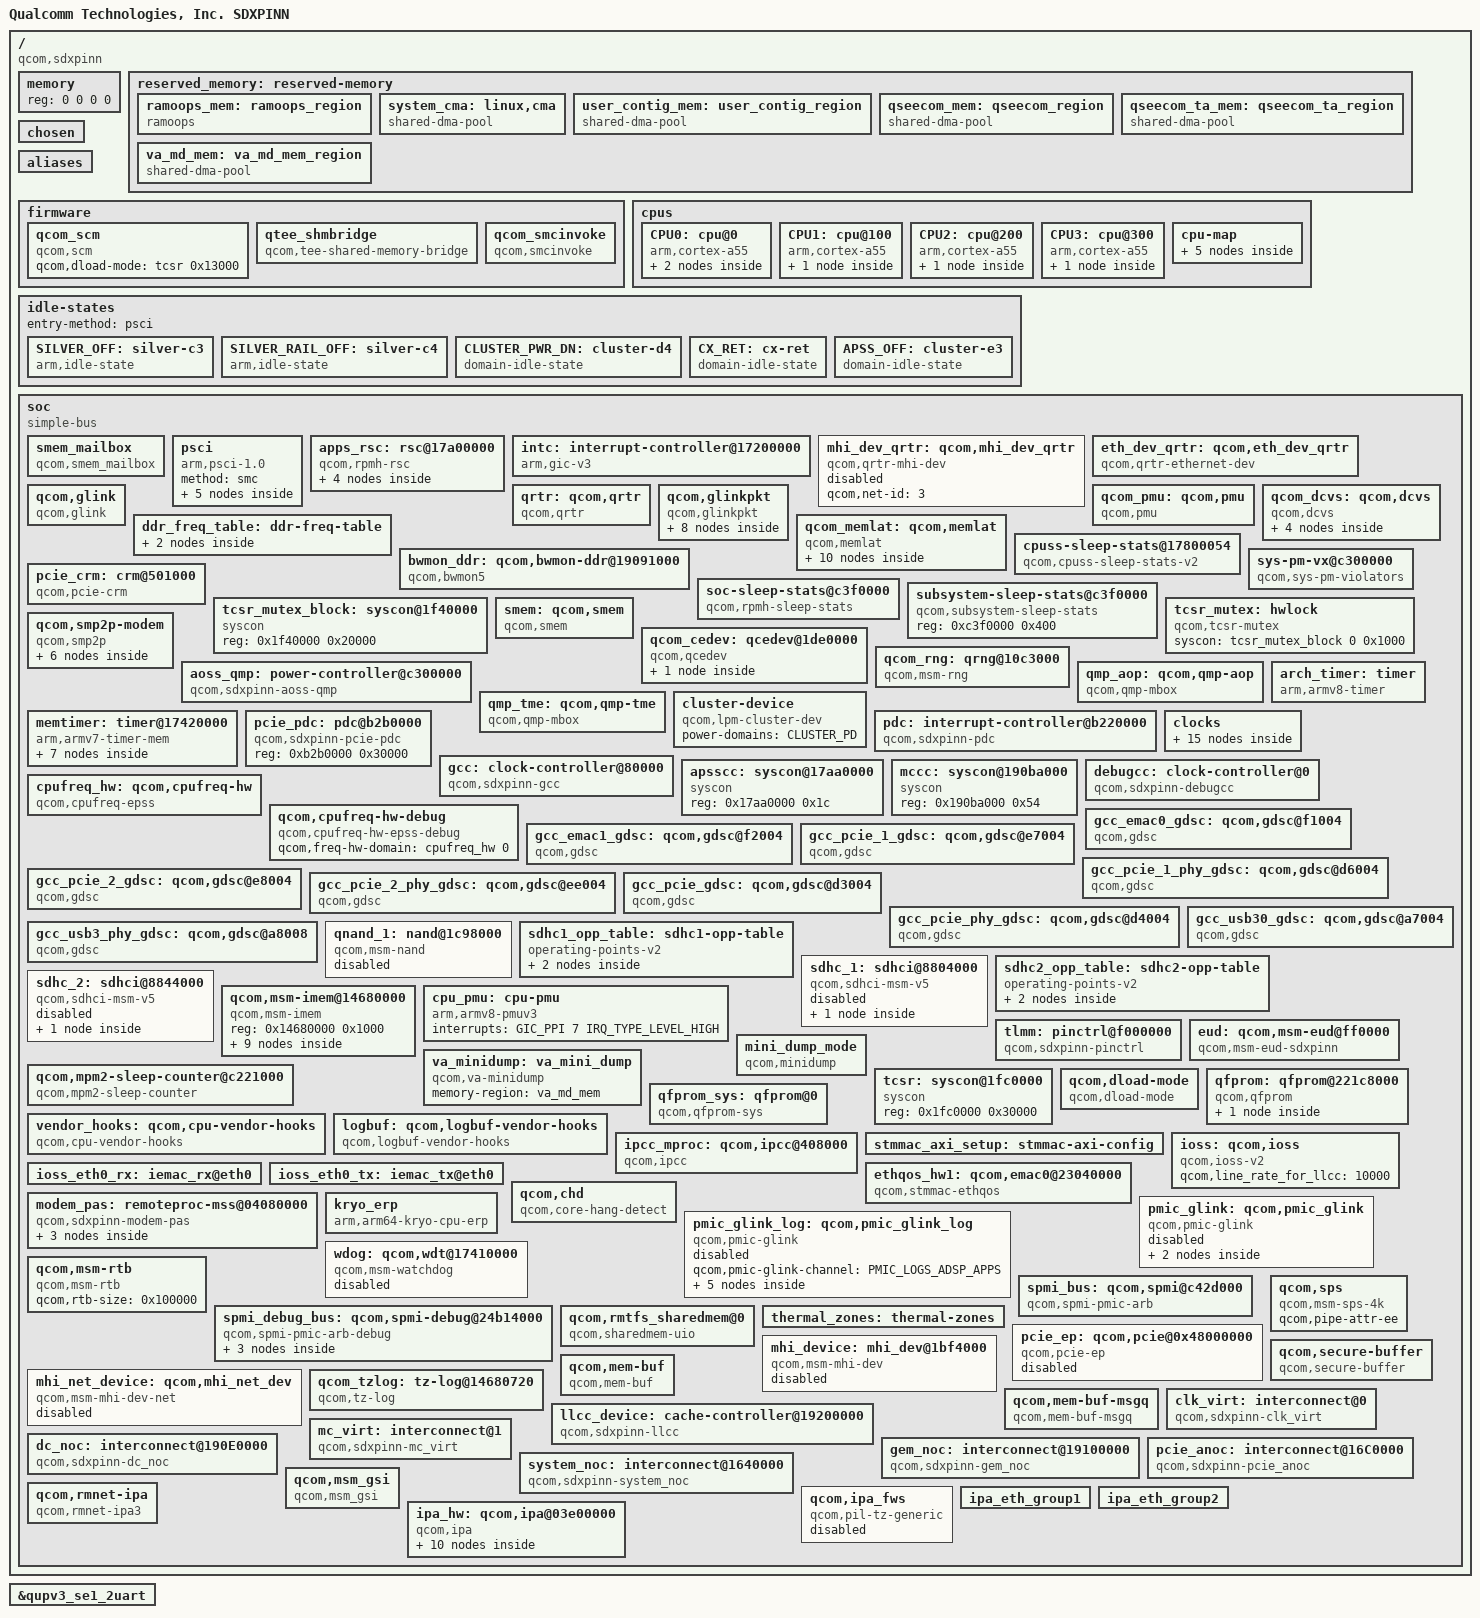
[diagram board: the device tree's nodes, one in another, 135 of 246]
// SPDX-License-Identifier: BSD-3-Clause
/*
 * Copyright (c) Qualcomm Technologies, Inc. and/or its subsidiaries.
 */

#include <dt-bindings/interrupt-controller/arm-gic.h>
#include <dt-bindings/clock/qcom,gcc-sdxpinn.h>
#include <dt-bindings/clock/qcom,rpmh.h>
#include <dt-bindings/soc/qcom,ipcc.h>
#include <dt-bindings/soc/qcom,rpmh-rsc.h>
#include <dt-bindings/gpio/gpio.h>
#include <dt-bindings/regulator/qcom,rpmh-regulator-levels.h>
#include <dt-bindings/spmi/spmi.h>
#include <dt-bindings/interconnect/qcom,icc.h>
#include <dt-bindings/interconnect/qcom,sdxpinn.h>

/ {
	model = "Qualcomm Technologies, Inc. SDXPINN";
	compatible = "qcom,sdxpinn";
	qcom,msm-id = <556 0x10000>, <580 0x10000>, <609 0x10000>, <610 0x10000>;
	interrupt-parent = <&intc>;

	#address-cells = <2>;
	#size-cells = <2>;
	memory { device_type = "memory"; reg = <0 0 0 0>; };

	reserved_memory: reserved-memory { };

	chosen: chosen {
		bootargs = "disable_dma32=on swiotlb=noforce kpti=off cpufreq.default_governor=performance pcie_ports=compat msm_rtb.filter=0x237 ftrace_dump_on_oops";
	};

	aliases {
		serial0 = &qupv3_se1_2uart;
		hsuart0 = &qupv3_se3_4uart;
		mmc0 = &sdhc_1; /*SDC1 eMMC & SD card slot*/
		mmc1 = &sdhc_2; /*SDC2 SD card slot*/
	};

	firmware: firmware { };

	cpus {
		#address-cells = <2>;
		#size-cells = <0>;

		CPU0: cpu@0 {
			device_type = "cpu";
			compatible = "arm,cortex-a55";
			reg = <0x0 0x0>;
			enable-method = "psci";
			cpu-idle-states = <&SILVER_OFF &SILVER_RAIL_OFF>;
			power-domains = <&CPU_PD0>;
			power-domain-names = "psci";
			cpu-release-addr = <0x0 0x90f00000>;
			next-level-cache = <&L2_0>;
			capacity-dmips-mhz = <1024>;
			dynamic-power-coefficient = <100>;
			#cooling-cells = <2>;
			qcom,freq-domain = <&cpufreq_hw 0>;
			L2_0: l2-cache {
				compatible = "arm,arch-cache";
				cache-level = <2>;
				next-level-cache = <&L3_0>;

				L3_0: l3-cache {
					compatible = "arm,arch-cache";
					cache-level = <3>;
				};
			};
		};

		CPU1: cpu@100 {
			device_type = "cpu";
			compatible = "arm,cortex-a55";
			reg = <0x0 0x100>;
			enable-method = "psci";
			cpu-idle-states = <&SILVER_OFF &SILVER_RAIL_OFF>;
			power-domains = <&CPU_PD1>;
			power-domain-names = "psci";
			cpu-release-addr = <0x0 0x90f00000>;
			capacity-dmips-mhz = <1024>;
			dynamic-power-coefficient = <100>;
			#cooling-cells = <2>;
			qcom,freq-domain = <&cpufreq_hw 0>;

			L2_1: l2-cache {
				compatible = "arm,arch-cache";
				cache-level = <2>;
				next-level-cache = <&L3_0>;
			};
		};

		CPU2: cpu@200 {
			device_type = "cpu";
			compatible = "arm,cortex-a55";
			reg = <0x0 0x200>;
			enable-method = "psci";
			cpu-idle-states = <&SILVER_OFF &SILVER_RAIL_OFF>;
			power-domains = <&CPU_PD2>;
			power-domain-names = "psci";
			cpu-release-addr = <0x0 0x90f00000>;
			capacity-dmips-mhz = <1024>;
			dynamic-power-coefficient = <100>;
			#cooling-cells = <2>;
			qcom,freq-domain = <&cpufreq_hw 0>;

			L2_2: l2-cache {
				compatible = "arm,arch-cache";
				cache-level = <2>;
				next-level-cache = <&L3_0>;
			};
		};

		CPU3: cpu@300 {
			device_type = "cpu";
			compatible = "arm,cortex-a55";
			reg = <0x0 0x300>;
			enable-method = "psci";
			cpu-idle-states = <&SILVER_OFF &SILVER_RAIL_OFF>;
			power-domains = <&CPU_PD3>;
			power-domain-names = "psci";
			cpu-release-addr = <0x0 0x90f00000>;
			capacity-dmips-mhz = <1024>;
			dynamic-power-coefficient = <100>;
			#cooling-cells = <2>;
			qcom,freq-domain = <&cpufreq_hw 0>;

			L2_3: l2-cache {
				compatible = "arm,arch-cache";
				cache-level = <2>;
				next-level-cache = <&L3_0>;
			};
		};

		cpu-map {
			cluster0 {
				core0 {
					cpu = <&CPU0>;
				};

				core1 {
					cpu = <&CPU1>;
				};

				core2 {
					cpu = <&CPU2>;
				};

				core3 {
					cpu = <&CPU3>;
				};
			};

		};
	};

	idle-states {
		entry-method = "psci";

		SILVER_OFF: silver-c3 { /* C3 */
			compatible = "arm,idle-state";
			idle-state-name = "pc";
			entry-latency-us = <235>;
			exit-latency-us = <428>;
			min-residency-us = <1774>;
			arm,psci-suspend-param = <0x40000003>;
			local-timer-stop;
		};

		SILVER_RAIL_OFF: silver-c4 { /* C4 */
			compatible = "arm,idle-state";
			idle-state-name = "rail-pc";
			entry-latency-us = <800>;
			exit-latency-us = <750>;
			min-residency-us = <4090>;
			arm,psci-suspend-param = <0x40000004>;
			local-timer-stop;
		};

		CLUSTER_PWR_DN: cluster-d4 { /* D4 */
			compatible = "domain-idle-state";
			idle-state-name = "l3-off";
			entry-latency-us = <1050>;
			exit-latency-us = <2500>;
			min-residency-us = <5309>;
			arm,psci-suspend-param = <0x41000044>;
		};

		CX_RET: cx-ret { /* Cx Ret */
			compatible = "domain-idle-state";
			idle-state-name = "cx-ret";
			entry-latency-us = <2761>;
			exit-latency-us = <3964>;
			min-residency-us = <8467>;
			arm,psci-suspend-param = <0x41001344>;
		};

		APSS_OFF: cluster-e3 { /* E3 */
			compatible = "domain-idle-state";
			idle-state-name = "llcc-off";
			entry-latency-us = <2793>;
			exit-latency-us = <4023>;
			min-residency-us = <9826>;
			arm,psci-suspend-param = <0x4100B344>;
		};
	};

	soc: soc { };
};

#include "sdxpinn-reserved-memory.dtsi"

&reserved_memory {
	#address-cells = <2>;
	#size-cells = <2>;
	ranges;

	ramoops_mem: ramoops_region {
		compatible = "ramoops";
		alloc-ranges = <0x0 0x00000000 0xffffffff 0xffffffff>;
		size = <0x0 0x200000>;
		pmsg-size = <0x200000>;
		mem-type = <2>;
	};

	/* global autoconfigured region for contiguous allocations */
	system_cma: linux,cma {
		compatible = "shared-dma-pool";
		alloc-ranges = <0x0 0x00000000 0x0 0xffffffff>;
		reusable;
		alignment = <0x0 0x400000>;
		size = <0x0 0x2000000>;
		linux,cma-default;
	};

	user_contig_mem: user_contig_region {
		compatible = "shared-dma-pool";
		alloc-ranges = <0x0 0x00000000 0x0 0xffffffff>;
		reusable;
		alignment = <0x0 0x400000>;
		size = <0x0 0x1000000>;
	};

	qseecom_mem: qseecom_region {
		compatible = "shared-dma-pool";
		alloc-ranges = <0x0 0x00000000 0x0 0xffffffff>;
		reusable;
		alignment = <0x0 0x400000>;
		size = <0x0 0x800000>;
	};

	qseecom_ta_mem: qseecom_ta_region {
		compatible = "shared-dma-pool";
		alloc-ranges = <0x0 0x00000000 0x0 0xffffffff>;
		reusable;
		alignment = <0x0 0x400000>;
		size = <0x0 0x400000>;
	};

	va_md_mem: va_md_mem_region {
		compatible = "shared-dma-pool";
		alloc-ranges = <0x0 0x00000000 0x0 0xffffffff>;
		reusable;
		size = <0x0 0x1000000>;
	};
};

&soc {
	#address-cells = <1>;
	#size-cells = <1>;
	ranges = <0 0 0 0xffffffff>;
	compatible = "simple-bus";

	smem_mailbox {
		compatible = "qcom,smem_mailbox";

		qcom,smem-states = <&smp2p_smem_mailbox_1_out 0>;
		qcom,smem-state-names = "smem-mailbox-smp2p-out";

		interrupts-extended = <&smp2p_smem_mailbox_1_in 0 0>,
					<&smp2p_smem_mailbox_1_in 1 0>,
					<&smp2p_smem_mailbox_1_in 2 0>,
					<&smp2p_smem_mailbox_1_in 3 0>;
		interrupt-names = "smem-mailbox-smp2p-1-in",
					"smem-mailbox-smp2p-2-in",
					"smem-mailbox-smp2p-3-in",
					"smem-mailbox-smp2p-4-in";
	};

	psci {
		compatible = "arm,psci-1.0";
		method = "smc";

		CPU_PD0: cpu-pd0 {
			#power-domain-cells = <0>;
			power-domains = <&CLUSTER_PD>;
		};

		CPU_PD1: cpu-pd1 {
			#power-domain-cells = <0>;
			power-domains = <&CLUSTER_PD>;
		};

		CPU_PD2: cpu-pd2 {
			#power-domain-cells = <0>;
			power-domains = <&CLUSTER_PD>;
		};

		CPU_PD3: cpu-pd3 {
			#power-domain-cells = <0>;
			power-domains = <&CLUSTER_PD>;
		};

		CLUSTER_PD: cluster-pd {
			#power-domain-cells = <0>;
			domain-idle-states = <&CLUSTER_PWR_DN &CX_RET &APSS_OFF>;
		};
	};

	apps_rsc: rsc@17a00000 {
		label = "apps_rsc";
		compatible = "qcom,rpmh-rsc";
		reg = <0x17a00000 0x10000>,
		      <0x17a10000 0x10000>,
		      <0x17a20000 0x10000>;
		reg-names = "drv-0", "drv-1", "drv-2";
		qcom,drv-count = <3>;
		interrupts = <GIC_SPI 3 IRQ_TYPE_LEVEL_HIGH>,
			     <GIC_SPI 4 IRQ_TYPE_LEVEL_HIGH>,
			     <GIC_SPI 5 IRQ_TYPE_LEVEL_HIGH>;
		power-domains = <&CLUSTER_PD>;

		apps_rsc_drv2: drv@2 {
			qcom,drv-id = <2>;
			qcom,tcs-offset = <0xd00>;
			channel@0 {
				qcom,tcs-config = <ACTIVE_TCS    3>,
						  <SLEEP_TCS     2>,
						  <WAKE_TCS      2>,
						  <CONTROL_TCS   0>,
						  <FAST_PATH_TCS 1>;
			};

			apps_bcm_voter: bcm_voter {
				compatible = "qcom,bcm-voter";
			};

			rpmhcc: clock-controller {
				compatible = "qcom,sdxpinn-rpmh-clk";
				#clock-cells = <1>;
			};
		};
	};

	intc: interrupt-controller@17200000 {
		compatible = "arm,gic-v3";
		#interrupt-cells = <3>;
		interrupt-controller;
		#redistributor-regions = <1>;
		redistributor-stride = <0x0 0x20000>;
		reg = <0x17200000 0x10000>,/* GICD */
				<0x17260000 0x80000>;/* GICR * 4 */
		interrupts = <GIC_PPI 9 IRQ_TYPE_LEVEL_HIGH>;
	};

	 mhi_dev_qrtr: qcom,mhi_dev_qrtr {
		compatible = "qcom,qrtr-mhi-dev";
		qcom,net-id = <3>;
		status = "disabled";
	};

	eth_dev_qrtr: qcom,eth_dev_qrtr {
		compatible = "qcom,qrtr-ethernet-dev";
		qcom,net-id = <4>;
		qcom,low-latency;
	};

	qrtr: qcom,qrtr {
		compatible = "qcom,qrtr";
	};

	qcom,glink {
		compatible = "qcom,glink";
	};

	qcom,glinkpkt {
		compatible = "qcom,glinkpkt";

		qcom,glinkpkt-at-mdm0 {
			qcom,glinkpkt-edge = "mpss";
			qcom,glinkpkt-ch-name = "DS";
			qcom,glinkpkt-dev-name = "at_mdm0";
		};

		qcom,glinkpkt-data5-cntl {
			qcom,glinkpkt-edge = "mpss";
			qcom,glinkpkt-ch-name = "DATA5_CNTL";
			qcom,glinkpkt-dev-name = "smdcntl0";
		};

		qcom,glinkpkt-data6-cntl {
			qcom,glinkpkt-edge = "mpss";
			qcom,glinkpkt-ch-name = "DATA6_CNTL";
			qcom,glinkpkt-dev-name = "smdcntl1";
		};

		qcom,glinkpkt-data40-cntl {
			qcom,glinkpkt-edge = "mpss";
			qcom,glinkpkt-ch-name = "DATA40_CNTL";
			qcom,glinkpkt-dev-name = "smdcntl8";
		};

		qcom,glinkpkt-data1 {
			qcom,glinkpkt-edge = "mpss";
			qcom,glinkpkt-ch-name = "DATA1";
			qcom,glinkpkt-dev-name = "smd7";
		};

		qcom,glinkpkt-data11 {
			qcom,glinkpkt-edge = "mpss";
			qcom,glinkpkt-ch-name = "DATA11";
			qcom,glinkpkt-dev-name = "smd11";
		};

		qcom,glinkpkt-data21 {
			qcom,glinkpkt-edge = "mpss";
			qcom,glinkpkt-ch-name = "DATA21";
			qcom,glinkpkt-dev-name = "smd21";
		};

		qcom,glinkpkt-data22 {
			qcom,glinkpkt-edge = "mpss";
			qcom,glinkpkt-ch-name = "DATA22";
			qcom,glinkpkt-dev-name = "smd22";
		};
	};

	qcom_pmu: qcom,pmu {
		compatible = "qcom,pmu";
		qcom,pmu-events-tbl =
			< 0x0008 0x0F 0xFF 0xFF >,
			< 0x0011 0x0F 0xFF 0xFF >,
			< 0x0017 0x0F 0xFF 0xFF >,
			< 0x002A 0xFF 0xFF 0xFF >;
	};

	ddr_freq_table: ddr-freq-table {
		ddr4 {
			qcom,ddr-type = <7>;
			qcom,freq-tbl =
				<  200000 >,
				<  451200 >,
				<  547200 >,
				<  681600 >,
				<  768000 >,
				< 1017600 >,
				< 1353600 >,
				< 1555200 >,
				< 1708800 >,
				< 2092800 >,
				< 2133000 >;
		};

		ddr5 {
			qcom,ddr-type = <8>;
			qcom,freq-tbl =
				<  200000 >,
				<  451200 >,
				<  547200 >,
				<  681600 >,
				<  768000 >,
				< 1555200 >,
				< 1708800 >,
				< 2092800 >,
				< 2736000 >,
				< 3196800 >;
		};
	};

	qcom_dcvs: qcom,dcvs {
		compatible = "qcom,dcvs";
		#address-cells = <1>;
		#size-cells = <1>;
		ranges;

		qcom_l3_dcvs_hw: l3 {
			compatible = "qcom,dcvs-hw";
			qcom,dcvs-hw-type = <2>;
			qcom,bus-width = <32>;
			reg = <0x17d90000 0x4000>, <0x17d90100 0xa0>;
			reg-names = "l3-base", "l3tbl-base";

			l3_dcvs_sp: sp {
				compatible = "qcom,dcvs-path";
				qcom,dcvs-path-type = <0>;
				qcom,shared-offset = <0x0090>;
			};
		};


		qcom_ddr_dcvs_hw: ddr {
			compatible = "qcom,dcvs-hw";
			qcom,dcvs-hw-type = <0>;
			qcom,bus-width = <4>;
			qcom,freq-tbl = <&ddr_freq_table>;

			ddr_dcvs_sp: sp {
				compatible = "qcom,dcvs-path";
				qcom,dcvs-path-type = <0>;
				interconnects = <&mc_virt MASTER_LLCC
						 &mc_virt SLAVE_EBI1>;
			};
		};

	};

	qcom_memlat: qcom,memlat {
		compatible = "qcom,memlat";
		ddr {
			compatible = "qcom,memlat-grp";
			qcom,target-dev = <&qcom_ddr_dcvs_hw>;
			qcom,sampling-path = <&ddr_dcvs_sp>;
			qcom,miss-ev = <0x2A>;

			silver {
				compatible = "qcom,memlat-mon";
				qcom,cpulist = <&CPU0 &CPU1 &CPU2 &CPU3>;
				qcom,sampling-enabled;
				ddr4-tbl {
					qcom,ddr-type = <7>;
					qcom,cpufreq-memfreq-tbl =
						<  691200  547200 >,
						<  806400  768000 >,
						< 1017600 1353600 >,
						< 1440000 1555200 >,
						< 1747200 2092800 >;
				};

				ddr5-tbl {
					qcom,ddr-type = <8>;
					qcom,cpufreq-memfreq-tbl =
						<  691200  547200 >,
						<  806400  768000 >,
						< 1017600 1708800 >,
						< 1440000 2092800 >,
						< 1747200 3196800 >;
				};
			};

			silver-compute {
				compatible = "qcom,memlat-mon";
				qcom,cpulist = <&CPU0 &CPU1 &CPU2 &CPU3>;
				qcom,sampling-enabled;
				qcom,compute-mon;
				ddr4-tbl {
					qcom,ddr-type = <7>;
					qcom,cpufreq-memfreq-tbl =
						< 1440000  547200 >,
						< 1747200 1353600 >;
				};

				ddr5-tbl {
					qcom,ddr-type = <8>;
					qcom,cpufreq-memfreq-tbl =
						< 1440000  547200 >,
						< 1747200 3196800 >;
				};
			};
		};

		l3 {
			compatible = "qcom,memlat-grp";
			qcom,target-dev = <&qcom_l3_dcvs_hw>;
			qcom,sampling-path = <&l3_dcvs_sp>;
			qcom,miss-ev = <0x17>;

			silver {
				compatible = "qcom,memlat-mon";
				qcom,cpulist = <&CPU0 &CPU1 &CPU2 &CPU3>;
				qcom,cpufreq-memfreq-tbl =
					<  691200  556800 >,
					<  806400  652800 >,
					< 1017600  844800 >,
					< 1440000 1036800 >,
					< 1747200 1440000 >;
					qcom,sampling-enabled;
			};

			silver-compute {
				compatible = "qcom,memlat-mon";
				qcom,cpulist = <&CPU0 &CPU1 &CPU2 &CPU3>;
				qcom,cpufreq-memfreq-tbl =
					< 1440000  556800 >,
					< 1747200 1440000 >;
					qcom,sampling-enabled;
					qcom,compute-mon;
			};
		};
	};

	bwmon_ddr: qcom,bwmon-ddr@19091000 {
		compatible = "qcom,bwmon5";
		reg = <0x19091000 0x1000>;
		reg-names = "base";
		interrupts = <GIC_SPI 257 IRQ_TYPE_LEVEL_HIGH>;
		qcom,hw-timer-hz = <19200000>;
		qcom,count-unit = <0x10000>;
		qcom,target-dev = <&qcom_ddr_dcvs_hw>;
	};

	cpuss-sleep-stats@17800054 {
		compatible = "qcom,cpuss-sleep-stats-v2";
		reg = <0x17800054 0x4>, <0x17810054 0x4>, <0x17820054 0x4>,
		      <0x17830054 0x4>, <0x17880098 0x4>, <0x178c0000 0x10000>;
		reg-names = "seq_lpm_cntr_cfg_cpu0", "seq_lpm_cntr_cfg_cpu1",
			    "seq_lpm_cntr_cfg_cpu2", "seq_lpm_cntr_cfg_cpu3",
			    "l3_seq_lpm_cntr_cfg", "apss_seq_mem_base";
		num-cpus = <4>;
	};

	sys-pm-vx@c300000 {
		compatible = "qcom,sys-pm-violators", "qcom,sys-pm-sdxpinn";
		reg = <0xc300000 0x0400>;
		mboxes = <&qmp_aop 0>;
		mbox-names = "aop";
	};

	pcie_crm: crm@501000 {
		label = "pcie_crm";
		compatible = "qcom,pcie-crm";
		reg = <0x501000 0x3000>;
		reg-names = "base";
		interrupts = <GIC_SPI 261 IRQ_TYPE_EDGE_RISING>;
		interrupt-names = "pcie_crm";
		clocks = <&pcie_pipe_clk>;
		qcom,hw-drv-ids = <0>;
		qcom,sw-drv-ids = <0>;
	};

	soc-sleep-stats@c3f0000 {
		compatible = "qcom,rpmh-sleep-stats";
		reg = <0xc3f0000 0x400>;
		ss-name = "modem", "adsp", "apss";
	};

	subsystem-sleep-stats@c3f0000 {
		compatible = "qcom,subsystem-sleep-stats";
		reg = <0xc3f0000 0x400>;
	};

	tcsr_mutex_block: syscon@1f40000 {
		compatible = "syscon";
		reg = <0x1f40000 0x20000>;
	};

	tcsr_mutex: hwlock {
		compatible = "qcom,tcsr-mutex";
		syscon = <&tcsr_mutex_block 0 0x1000>;
		#hwlock-cells = <1>;
	};

	smem: qcom,smem {
		compatible = "qcom,smem";
		memory-region = <&smem_mem>;
		hwlocks = <&tcsr_mutex 3>;
	};

	qcom_cedev: qcedev@1de0000 {
		compatible = "qcom,qcedev";
		reg = <0x1de0000 0x20000>,
			<0x1dc4000 0x28000>;
		reg-names = "crypto-base","crypto-bam-base";
		interrupts = <GIC_SPI 252 IRQ_TYPE_LEVEL_HIGH>;
		qcom,bam-pipe-pair = <2>;
		qcom,ce-hw-instance = <0>;
		qcom,ce-device = <0>;
		qcom,ce-hw-shared;
		qcom,bam-ee = <0>;
		qcom,smmu-s1-enable;
		qcom,no-clock-support;
		interconnect-names = "data_path";
		interconnects = <&system_noc MASTER_CRYPTO &mc_virt SLAVE_EBI1>;
		iommus = <&apps_smmu 0x0020 0x0>,
			<&apps_smmu 0x0021 0x0>;
		qcom,iommu-dma = "atomic";
		dma-coherent;

		qcom_cedev_ns_cb {
			compatible = "qcom,qcedev,context-bank";
			label = "ns_context";
			iommus = <&apps_smmu 0x0021 0x0>;
			dma-coherent;
		};
	};

	qcom_rng: qrng@10c3000 {
		compatible = "qcom,msm-rng";
		reg = <0x10c3000 0x1000>;
		qcom,no-qrng-config;
		qcom,no-clock-support;
	};

	qcom,smp2p-modem {
		compatible = "qcom,smp2p";
		qcom,smem = <435>, <428>;
		interrupt-parent = <&ipcc_mproc>;
		interrupts = <IPCC_CLIENT_MPSS IPCC_MPROC_SIGNAL_SMP2P
				IRQ_TYPE_EDGE_RISING>;
		mboxes = <&ipcc_mproc IPCC_CLIENT_MPSS IPCC_MPROC_SIGNAL_SMP2P>;
		qcom,local-pid = <0>;
		qcom,remote-pid = <1>;

		modem_smp2p_out: master-kernel {
			qcom,entry-name = "master-kernel";
			#qcom,smem-state-cells = <1>;
		};

		modem_smp2p_in: slave-kernel {
			qcom,entry-name = "slave-kernel";
			interrupt-controller;
			#interrupt-cells = <2>;
		};

		smp2p_ipa_1_out: qcom,smp2p-ipa-1-out {
			qcom,entry-name = "ipa";
			#qcom,smem-state-cells = <1>;
		};

		 /* ipa - inbound entry from mss */
		smp2p_ipa_1_in: qcom,smp2p-ipa-1-in {
			qcom,entry-name = "ipa";
			interrupt-controller;
			#interrupt-cells = <2>;
		};

		smp2p_smem_mailbox_1_out: qcom,smp2p-smem-mailbox-1-out {
			qcom,entry-name = "smem-mailbox";
			#qcom,smem-state-cells = <1>;
		};

		smp2p_smem_mailbox_1_in: qcom,smp2p-smem-mailbox-1-in {
			qcom,entry-name = "smem-mailbox";
			interrupt-controller;
			#interrupt-cells = <2>;
		};
	};

	aoss_qmp: power-controller@c300000 {
		compatible = "qcom,sdxpinn-aoss-qmp";
		reg = <0xc310000 0x1000>;
		interrupt-parent = <&ipcc_mproc>;
		interrupts = <IPCC_CLIENT_AOP
				IPCC_MPROC_SIGNAL_GLINK_QMP
				IRQ_TYPE_EDGE_RISING>;
		mboxes = <&ipcc_mproc IPCC_CLIENT_AOP
				IPCC_MPROC_SIGNAL_GLINK_QMP>;

		#power-domain-cells = <1>;
		#clock-cells = <0>;
	};

	qmp_aop: qcom,qmp-aop {
		compatible = "qcom,qmp-mbox";
		qcom,qmp = <&aoss_qmp>;
		label = "aop";
		#mbox-cells = <1>;
	};

	qmp_tme: qcom,qmp-tme {
		compatible = "qcom,qmp-mbox";
		qcom,remote-pid = <14>;
		mboxes = <&ipcc_mproc IPCC_CLIENT_TME
			  IPCC_MPROC_SIGNAL_GLINK_QMP>;
		mbox-names = "tme_qmp";
		interrupt-parent = <&ipcc_mproc>;
		interrupts = <IPCC_CLIENT_TME
			      IPCC_MPROC_SIGNAL_GLINK_QMP
			      IRQ_TYPE_EDGE_RISING>;

		label = "tme";
		qcom,early-boot;
		priority = <0>;
		mbox-desc-offset = <0x0>;
		#mbox-cells = <1>;
	};

	cpuss-sleep-stats@17800054 {
		compatible = "qcom,cpuss-sleep-stats-v2";
		reg = <0x17800054 0x4>, <0x17810054 0x4>, <0x17820054 0x4>,
		      <0x17830054 0x4>, <0x17880098 0x4>, <0x178c0000 0x10000>;
		reg-names = "seq_lpm_cntr_cfg_cpu0", "seq_lpm_cntr_cfg_cpu1",
			    "seq_lpm_cntr_cfg_cpu2", "seq_lpm_cntr_cfg_cpu3",
			    "l3_seq_lpm_cntr_cfg", "apss_seq_mem_base";
		num-cpus = <4>;
	};

	soc-sleep-stats@c3f0000 {
		compatible = "qcom,rpmh-sleep-stats";
		reg = <0xc3f0000 0x400>;
		ss-name = "modem", "adsp", "apss";
	};

	subsystem-sleep-stats@c3f0000 {
		compatible = "qcom,subsystem-sleep-stats";
		reg = <0xc3f0000 0x400>;
	};

	arch_timer: timer {
		compatible = "arm,armv8-timer";
		interrupts = <GIC_PPI 13 (GIC_CPU_MASK_SIMPLE(8) | IRQ_TYPE_LEVEL_LOW)>,
					<GIC_PPI 14 (GIC_CPU_MASK_SIMPLE(8) | IRQ_TYPE_LEVEL_LOW)>,
					<GIC_PPI 11 (GIC_CPU_MASK_SIMPLE(8) | IRQ_TYPE_LEVEL_LOW)>,
					<GIC_PPI 12 (GIC_CPU_MASK_SIMPLE(8) | IRQ_TYPE_LEVEL_LOW)>;
		clock-frequency = <19200000>;
	};

	cluster-device {
		compatible = "qcom,lpm-cluster-dev";
		power-domains = <&CLUSTER_PD>;
	};

	memtimer: timer@17420000 {
		#address-cells = <1>;
		#size-cells = <1>;
		ranges;
		compatible = "arm,armv7-timer-mem";
		reg = <0x17420000 0x1000>;
		clock-frequency = <19200000>;

		frame@17421000 {
			frame-number = <0>;
			interrupts = <GIC_SPI 8 IRQ_TYPE_LEVEL_HIGH>,
						<GIC_SPI 6 IRQ_TYPE_LEVEL_HIGH>;
			reg = <0x17421000 0x1000>,
				<0x17422000 0x1000>;
		};

		frame@17423000 {
			frame-number = <1>;
			interrupts = <GIC_SPI 9 IRQ_TYPE_LEVEL_HIGH>;
			reg = <0x17423000 0x1000>;
			status = "disabled";
		};

		frame@17425000 {
			frame-number = <2>;
			interrupts = <GIC_SPI 10 IRQ_TYPE_LEVEL_HIGH>;
			reg = <0x17425000 0x1000>;
			status = "disabled";
		};

		frame@17427000 {
			frame-number = <3>;
			interrupts = <GIC_SPI 11 IRQ_TYPE_LEVEL_HIGH>;
			reg = <0x17427000 0x1000>;
			status = "disabled";
		};

		frame@17429000 {
			frame-number = <4>;
			interrupts = <GIC_SPI 12 IRQ_TYPE_LEVEL_HIGH>;
			reg = <0x17429000 0x1000>;
			status = "disabled";
		};

		frame@1742b000 {
			frame-number = <5>;
			interrupts = <GIC_SPI 13 IRQ_TYPE_LEVEL_HIGH>;
			reg = <0x1742b000 0x1000>;
			status = "disabled";
		};

		frame@1742d000 {
			frame-number = <6>;
			interrupts = <GIC_SPI 14 IRQ_TYPE_LEVEL_HIGH>;
			reg = <0x1742d000 0x1000>;
			status = "disabled";
		};
	};

	pdc: interrupt-controller@b220000 {
		compatible = "qcom,sdxpinn-pdc", "qcom,pdc";
		reg = <0xb220000 0x30000>, <0x174000f0 0x64>;
		qcom,pdc-ranges = <0 147 52>, <52 266 32>, <84 500 59>;
		#interrupt-cells = <2>;
		interrupt-parent = <&intc>;
		interrupt-controller;
	};

	pcie_pdc: pdc@b2b0000 {
		compatible = "qcom,sdxpinn-pcie-pdc", "qcom,pcie-pdc";
		reg = <0xb2b0000 0x30000>;
	};

	clocks {
		xo_board: xo_board {
			compatible = "fixed-clock";
			clock-frequency = <76800000>;
			clock-output-names = "xo_board";
			#clock-cells = <0>;
		};

		sleep_clk: sleep_clk {
			compatible = "fixed-clock";
			clock-frequency = <32000>;
			clock-output-names = "sleep_clk";
			#clock-cells = <0>;
		};

		emac0_sgmiiphy_mac_rclk: emac0_sgmiiphy_mac_rclk {
			compatible = "fixed-clock";
			clock-frequency = <1000>;
			clock-output-names = "emac0_sgmiiphy_mac_rclk";
			#clock-cells = <0>;
		};

		emac0_sgmiiphy_mac_tclk: emac0_sgmiiphy_mac_tclk {
			compatible = "fixed-clock";
			clock-frequency = <1000>;
			clock-output-names = "emac0_sgmiiphy_mac_tclk";
			#clock-cells = <0>;
		};

		emac0_sgmiiphy_rclk: emac0_sgmiiphy_rclk {
			compatible = "fixed-clock";
			clock-frequency = <1000>;
			clock-output-names = "emac0_sgmiiphy_rclk";
			#clock-cells = <0>;
		};

		emac0_sgmiiphy_tclk: emac0_sgmiiphy_tclk {
			compatible = "fixed-clock";
			clock-frequency = <1000>;
			clock-output-names = "emac0_sgmiiphy_tclk";
			#clock-cells = <0>;
		};

		emac1_sgmiiphy_mac_rclk: emac1_sgmiiphy_mac_rclk {
			compatible = "fixed-clock";
			clock-frequency = <1000>;
			clock-output-names = "emac1_sgmiiphy_mac_rclk";
			#clock-cells = <0>;
		};

		emac1_sgmiiphy_mac_tclk: emac1_sgmiiphy_mac_tclk {
			compatible = "fixed-clock";
			clock-frequency = <1000>;
			clock-output-names = "emac1_sgmiiphy_mac_tclk";
			#clock-cells = <0>;
		};

		emac1_sgmiiphy_rclk: emac1_sgmiiphy_rclk {
			compatible = "fixed-clock";
			clock-frequency = <1000>;
			clock-output-names = "emac1_sgmiiphy_rclk";
			#clock-cells = <0>;
		};

		emac1_sgmiiphy_tclk: emac1_sgmiiphy_tclk {
			compatible = "fixed-clock";
			clock-frequency = <1000>;
			clock-output-names = "emac1_sgmiiphy_tclk";
			#clock-cells = <0>;
		};

		pcie20_phy_aux_clk: pcie20_phy_aux_clk {
			compatible = "fixed-clock";
			clock-frequency = <1000>;
			clock-output-names = "pcie20_phy_aux_clk";
			#clock-cells = <0>;
		};

		pcie_1_pipe_clk: pcie_1_pipe_clk {
			compatible = "fixed-clock";
			clock-frequency = <1000>;
			clock-output-names = "pcie_1_pipe_clk";
			#clock-cells = <0>;
		};

		pcie_2_pipe_clk: pcie_2_pipe_clk {
			compatible = "fixed-clock";
			clock-frequency = <1000>;
			clock-output-names = "pcie_2_pipe_clk";
			#clock-cells = <0>;
		};

		pcie_pipe_clk: pcie_pipe_clk {
			compatible = "fixed-clock";
			clock-frequency = <1000>;
			clock-output-names = "pcie_pipe_clk";
			#clock-cells = <0>;
		};

		usb3_phy_wrapper_gcc_usb30_pipe_clk: usb3_phy_wrapper_gcc_usb30_pipe_clk {
			compatible = "fixed-clock";
			clock-frequency = <1000>;
			clock-output-names = "usb3_phy_wrapper_gcc_usb30_pipe_clk";
			#clock-cells = <0>;
		};
	};

	gcc: clock-controller@80000 {
		compatible = "qcom,sdxpinn-gcc", "syscon";
		reg = <0x80000 0x1f4200>;
		reg-name = "cc_base";
		vdd_cx-supply = <&VDD_CX_LEVEL>;
		vdd_mx-supply = <&VDD_MXA_LEVEL>;
		clocks = <&rpmhcc RPMH_CXO_CLK>,
			 <&emac0_sgmiiphy_mac_rclk>,
			 <&emac0_sgmiiphy_mac_tclk>,
			 <&emac0_sgmiiphy_rclk>,
			 <&emac0_sgmiiphy_tclk>,
			 <&emac1_sgmiiphy_mac_rclk>,
			 <&emac1_sgmiiphy_mac_tclk>,
			 <&emac1_sgmiiphy_rclk>,
			 <&emac1_sgmiiphy_tclk>,
			 <&pcie20_phy_aux_clk>,
			 <&pcie_1_pipe_clk>,
			 <&pcie_2_pipe_clk>,
			 <&pcie_pipe_clk>,
			 <&sleep_clk>,
			 <&usb3_phy_wrapper_gcc_usb30_pipe_clk>;
		clock-names = "bi_tcxo",
			      "emac0_sgmiiphy_mac_rclk",
			      "emac0_sgmiiphy_mac_tclk",
			      "emac0_sgmiiphy_rclk",
			      "emac0_sgmiiphy_tclk",
			      "emac1_sgmiiphy_mac_rclk",
			      "emac1_sgmiiphy_mac_tclk",
			      "emac1_sgmiiphy_rclk",
			      "emac1_sgmiiphy_tclk",
			      "pcie20_phy_aux_clk",
			      "pcie_1_pipe_clk",
			      "pcie_2_pipe_clk",
			      "pcie_pipe_clk",
			      "sleep_clk",
			      "usb3_phy_wrapper_gcc_usb30_pipe_clk";
		protected-clocks = <GCC_TLMM_125_CLK>,
				<GCC_TLMM_125_CLK_SRC>;
		#clock-cells = <1>;
		#reset-cells = <1>;
	};

	apsscc: syscon@17aa0000 {
		compatible = "syscon";
		reg = <0x17aa0000 0x1c>;
	};

	mccc: syscon@190ba000 {
		compatible = "syscon";
		reg = <0x190ba000 0x54>;
	};

	debugcc: clock-controller@0 {
		compatible = "qcom,sdxpinn-debugcc";
		qcom,apsscc = <&apsscc>;
		qcom,gcc = <&gcc>;
		qcom,mccc = <&mccc>;
		clocks = <&rpmhcc RPMH_CXO_CLK>,
			<&gcc 0>;
		clock-names = "xo_clk_src",
			"gcc";
		#clock-cells = <1>;
	};

	cpufreq_hw: qcom,cpufreq-hw {
		compatible = "qcom,cpufreq-epss";
		reg = <0x17d91000 0x1000>;
		reg-names = "freq-domain0";
		clocks = <&rpmhcc RPMH_CXO_CLK>, <&gcc GPLL0>;
		clock-names = "xo", "alternate";
		interrupts = <GIC_SPI 30 IRQ_TYPE_LEVEL_HIGH>;
		interrupt-names = "dcvsh0_int";
		#freq-domain-cells = <1>;
	};

	qcom,cpufreq-hw-debug {
		compatible = "qcom,cpufreq-hw-epss-debug";
		qcom,freq-hw-domain = <&cpufreq_hw 0>;
	};

	/* GCC GDSCs */
	gcc_emac0_gdsc: qcom,gdsc@f1004 {
		compatible = "qcom,gdsc";
		reg = <0xf1004 0x4>;
		regulator-name = "gcc_emac0_gdsc";
		parent-supply = <&VDD_CX_LEVEL>;
		qcom,retain-regs;
		qcom,support-hw-trigger;
	};

	gcc_emac1_gdsc: qcom,gdsc@f2004 {
		compatible = "qcom,gdsc";
		reg = <0xf2004 0x4>;
		regulator-name = "gcc_emac1_gdsc";
		parent-supply = <&VDD_CX_LEVEL>;
		qcom,retain-regs;
		qcom,support-hw-trigger;
	};

	gcc_pcie_1_gdsc: qcom,gdsc@e7004 {
		compatible = "qcom,gdsc";
		reg = <0xe7004 0x4>;
		regulator-name = "gcc_pcie_1_gdsc";
		parent-supply = <&VDD_CX_LEVEL>;
		qcom,retain-regs;
		qcom,support-hw-trigger;
	};

	gcc_pcie_1_phy_gdsc: qcom,gdsc@d6004 {
		compatible = "qcom,gdsc";
		reg = <0xd6004 0x4>;
		regulator-name = "gcc_pcie_1_phy_gdsc";
		parent-supply = <&VDD_MXA_LEVEL>;
		qcom,retain-regs;
		qcom,support-hw-trigger;
	};

	gcc_pcie_2_gdsc: qcom,gdsc@e8004 {
		compatible = "qcom,gdsc";
		reg = <0xe8004 0x4>;
		regulator-name = "gcc_pcie_2_gdsc";
		parent-supply = <&VDD_CX_LEVEL>;
		qcom,retain-regs;
		qcom,support-hw-trigger;
	};

	gcc_pcie_2_phy_gdsc: qcom,gdsc@ee004 {
		compatible = "qcom,gdsc";
		reg = <0xee004 0x4>;
		regulator-name = "gcc_pcie_2_phy_gdsc";
		parent-supply = <&VDD_MXA_LEVEL>;
		qcom,retain-regs;
		qcom,support-hw-trigger;
	};

	gcc_pcie_gdsc: qcom,gdsc@d3004 {
		compatible = "qcom,gdsc";
		reg = <0xd3004 0x4>;
		regulator-name = "gcc_pcie_gdsc";
		parent-supply = <&VDD_MXA_LEVEL>;
		qcom,retain-regs;
		qcom,support-hw-trigger;
	};

	gcc_pcie_phy_gdsc: qcom,gdsc@d4004 {
		compatible = "qcom,gdsc";
		reg = <0xd4004 0x4>;
		regulator-name = "gcc_pcie_phy_gdsc";
		parent-supply = <&VDD_MXA_LEVEL>;
		qcom,retain-regs;
		qcom,support-hw-trigger;
	};

	gcc_usb30_gdsc: qcom,gdsc@a7004 {
		compatible = "qcom,gdsc";
		reg = <0xa7004 0x4>;
		regulator-name = "gcc_usb30_gdsc";
		parent-supply = <&VDD_MXA_LEVEL>;
		qcom,retain-regs;
	};

	gcc_usb3_phy_gdsc: qcom,gdsc@a8008 {
		compatible = "qcom,gdsc";
		reg = <0xa8008 0x4>;
		regulator-name = "gcc_usb3_phy_gdsc";
		parent-supply = <&VDD_CX_LEVEL>;
		qcom,retain-regs;
	};

	qnand_1: nand@1c98000 {
		compatible = "qcom,msm-nand";
		reg =   <0x01c98000 0x1000>,
			<0x01c9C000 0x1c000>;
		reg-names =     "nand_phys",
				"bam_phys";
		qcom,reg-adjustment-offset = <0x4000>;

		interrupts = <GIC_SPI 135 IRQ_TYPE_LEVEL_HIGH>;
		interrupt-names = "bam_irq";

		clock-names = "core_clk";
		clocks = <&rpmhcc RPMH_QPIC_CLK>;

		interconnects = <&system_noc MASTER_QPIC &mc_virt SLAVE_EBI1>;
		interconnect-names = "nand-ddr";
		qcom,msm-bus,name = "qpic_nand";
		qcom,msm-bus,num-cases = <2>;
		qcom,msm-bus,num-paths = <1>;
		qcom,msm-bus,vectors-KBps =
			<0 0>,
		/* Voting for max b/w on PNOC bus for now */
			<1057800 725760>;

		iommus = <&apps_smmu 0x100 0x3>;
		qcom,iommu-dma = "atomic";
		dma-coherent;

		status = "disabled";
	};

	sdhc1_opp_table: sdhc1-opp-table {
		compatible = "operating-points-v2";

		opp-100000000 {
			opp-hz = /bits/ 64 <100000000>;
			opp-peak-kBps = <1600000 56000>;
			opp-avg-kBps = <104000 0>;
		};

		opp-384000000 {
			opp-hz = /bits/ 64 <384000000>;
			opp-peak-kBps = <7000000 360000>;
			opp-avg-kBps = <400000 0>;
		};
	};

	sdhc_1: sdhci@8804000 {
		status = "disabled";

		compatible = "qcom,sdhci-msm-v5";
		reg = <0x08804000 0x1000>;
		reg-names = "hc";

		interrupts = <GIC_SPI 210 IRQ_TYPE_LEVEL_HIGH>,
				<GIC_SPI 227 IRQ_TYPE_LEVEL_HIGH>;
		interrupt-names = "hc_irq", "pwr_irq";

		bus-width = <4>;
		no-sdio;
		qcom,restore-after-cx-collapse;
		qcom,no-partial-init;

		clocks = <&gcc GCC_SDCC1_AHB_CLK>,
			<&gcc GCC_SDCC1_APPS_CLK>;
		clock-names = "iface", "core";

		/* DLL HSR settings. Refer go/hsr - <Target> DLL settings */
		qcom,dll-hsr-list = <0x0007442C 0x0 0x10
					0x090106C0 0x80040868>;

		iommus = <&apps_smmu 0x00A0 0x0>;
		dma-coherent;
		qcom,iommu-dma = "fastmap";
		qcom,iommu-dma-addr-pool = <0x20000000 0x10000000>;
		qcom,iommu-geometry = <0x20000000 0x10000000>;

		interconnects = <&system_noc MASTER_SDCC_1 &mc_virt SLAVE_EBI1>,
			<&gem_noc MASTER_APPSS_PROC &system_noc SLAVE_SDCC_1>;
		interconnect-names = "sdhc-ddr","cpu-sdhc";
		operating-points-v2 = <&sdhc1_opp_table>;

		qos0 {
			mask = <0x0f>;
			vote = <44>;
		};
	};

	sdhc2_opp_table: sdhc2-opp-table {
		compatible = "operating-points-v2";

		opp-100000000 {
			opp-hz = /bits/ 64 <100000000>;
			opp-peak-kBps = <1600000 56000>;
			opp-avg-kBps = <50000 0>;
		};

		opp-202000000 {
			opp-hz = /bits/ 64 <202000000>;
			opp-peak-kBps = <7000000 360000>;
			opp-avg-kBps = <104000 0>;
		};
	};

	sdhc_2: sdhci@8844000 {
		status = "disabled";

		compatible = "qcom,sdhci-msm-v5";
		reg = <0x08844000 0x1000>;
		reg-names = "hc";

		interrupts = <GIC_SPI 90 IRQ_TYPE_LEVEL_HIGH>,
				<GIC_SPI 411 IRQ_TYPE_LEVEL_HIGH>;
		interrupt-names = "hc_irq", "pwr_irq";

		bus-width = <4>;
		no-sdio;
		no-mmc;
		qcom,restore-after-cx-collapse;

		clocks = <&gcc GCC_SDCC2_AHB_CLK>,
			<&gcc GCC_SDCC2_APPS_CLK>;
		clock-names = "iface", "core";

		qcom,dll-hsr-list = <0x0007442C 0x0 0x10
					0x090106C0 0x80040868>;

		iommus = <&apps_smmu 0x00C0 0x0>;
		dma-coherent;
		qcom,iommu-dma = "fastmap";

		interconnects = <&system_noc MASTER_SDCC_4 &mc_virt SLAVE_EBI1>,
			<&gem_noc MASTER_APPSS_PROC &system_noc SLAVE_SDCC_4>;
		interconnect-names = "sdhc-ddr","cpu-sdhc";
		operating-points-v2 = <&sdhc2_opp_table>;

		qos0 {
			mask = <0x0f>;
			vote = <44>;
		};
	};

	qcom,msm-imem@14680000 {
		compatible = "qcom,msm-imem";
		reg = <0x14680000 0x1000>;
		ranges = <0x0 0x14680000 0x1000>;
		#address-cells = <1>;
		#size-cells = <1>;

		mem_dump_table@10  {
			compatible = "qcom,msm-imem-mem_dump_table";
			reg = <0x10 0x8>;
		};

		restart_reason@65c {
			compatible = "qcom,msm-imem-restart_reason";
			reg = <0x65c 0x4>;
		};

		dload_type@1c {
			compatible = "qcom,msm-imem-dload-type";
			reg = <0x1c 0x4>;
		};

		boot_stats@6b0 {
			compatible = "qcom,msm-imem-boot_stats";
			reg = <0x6b0 0x20>;
		};

		kaslr_offset@6d0 {
			compatible = "qcom,msm-imem-kaslr_offset";
			reg = <0x6d0 0xc>;
		};

		pil@94c {
			compatible = "qcom,pil-reloc-info";
			reg = <0x94c 0xc8>;
		};

		pil@6dc {
			compatible = "qcom,msm-imem-pil-disable-timeout";
			reg = <0x6dc 0x4>;
		};

		diag_dload@c8 {
			compatible = "qcom,msm-imem-diag-dload";
			reg = <0xc8 0xc8>;
		};

		modem_dsm@c98 {
			compatible = "qcom,msm-imem-mss-dsm";
			reg = <0xc98 0x10>;
		};
	};

	cpu_pmu: cpu-pmu {
		compatible = "arm,armv8-pmuv3";
		interrupts = <GIC_PPI 7 IRQ_TYPE_LEVEL_HIGH>;
	};

	tlmm: pinctrl@f000000 {
		compatible = "qcom,sdxpinn-pinctrl";
		reg = <0x0F000000 0x400000>;
		interrupts = <GIC_SPI 212 IRQ_TYPE_LEVEL_HIGH>;
		gpio-controller;
		#gpio-cells = <2>;
		interrupt-controller;
		#interrupt-cells = <2>;
		wakeup-parent = <&pdc>;
		qcom,gpios-reserved = <110 111 112 113 114 115>;
	};

	eud: qcom,msm-eud@ff0000 {
		compatible = "qcom,msm-eud-sdxpinn";
		interrupt-names = "eud_irq";
		interrupt-parent = <&pdc>;
		interrupts = <6 IRQ_TYPE_LEVEL_HIGH>;
		reg = <0xff0000 0x2000>,
			<0xff2000 0x1000>;
		reg-names = "eud_base", "eud_mode_mgr2";
		qcom,secure-eud-en;
	};

	mini_dump_mode {
		compatible = "qcom,minidump";
	};

	va_minidump: va_mini_dump {
		compatible = "qcom,va-minidump";
		memory-region = <&va_md_mem>;
	};

	qcom,mpm2-sleep-counter@c221000 {
		compatible = "qcom,mpm2-sleep-counter";
		reg = <0xc221000 0x1000>;
		clock-frequency = <32768>;
	};

	tcsr: syscon@1fc0000 {
		compatible = "syscon";
		reg = <0x1fc0000 0x30000>;
	};

	qcom,dload-mode {
		compatible = "qcom,dload-mode";
	};

	vendor_hooks: qcom,cpu-vendor-hooks {
		compatible = "qcom,cpu-vendor-hooks";
	};

	logbuf: qcom,logbuf-vendor-hooks {
		compatible = "qcom,logbuf-vendor-hooks";
	};

	qfprom: qfprom@221c8000 {
		compatible = "qcom,qfprom";
		reg = <0x221c8000 0x1000>;
		#address-cells = <1>;
		#size-cells = <1>;
		read-only;
		ranges;

		boot_config: boot_config@600 {
			reg = <0x600 0x1>;
		};
	};

	qfprom_sys: qfprom@0 {
		compatible = "qcom,qfprom-sys";
		nvmem-cells = <&boot_config>;
		nvmem-cell-names = "boot_config";
	};

	ipcc_mproc: qcom,ipcc@408000 {
		compatible = "qcom,ipcc";
		reg = <0x408000 0x1000>;
		interrupts = <GIC_SPI 241 IRQ_TYPE_LEVEL_HIGH>;
		interrupt-controller;
		#interrupt-cells = <3>;
		#mbox-cells = <2>;
	};

	stmmac_axi_setup: stmmac-axi-config {
		snps,wr_osr_lmt = <15>;
		snps,rd_osr_lmt = <15>;
		snps,axi_kbbe;
		/* If FB is disabled, the AXI master chooses
		 * a burst length of any value less than the
		 * maximum enabled burst length
		 * (all lesser burst length enables are redundant).
		 */
		snps,blen = <0 0 0 0 0 0 0>;
	};

	ioss: qcom,ioss {
		compatible = "qcom,ioss-v2";
		qcom,line_rate_for_llcc = <10000>;
	};

	ioss_eth0_rx: iemac_rx@eth0 {
		qcom,dir-rx;
		qcom,rx-filter-be;

		qcom,ring-size = <1024>;
		qcom,buff-size = <2048>;

		qcom,mod-count-min = <16>;
		qcom,mod-count-max = <16>;
		qcom,mod-usecs-min = <30>;
		qcom,mod-usecs-max = <60>;
	};

	ioss_eth0_tx: iemac_tx@eth0 {
		qcom,dir-tx;

		qcom,ring-size = <1024>;
		qcom,buff-size = <2048>;

		qcom,mod-count-min = <16>;
		qcom,mod-count-max = <16>;
		qcom,mod-usecs-min = <30>;
		qcom,mod-usecs-max = <60>;
	};

	ethqos_hw1: qcom,emac0@23040000 {
		compatible = "qcom,stmmac-ethqos", "snps,dwxgmac", "qcom,ioss-v2-device";
		qcom,arm-smmu;
		qcom,ioss = <&ioss>;
		qcom,ioss_instance = <0>;
		qcom,ioss_channels =
			<&ioss_eth0_rx>,
			<&ioss_eth0_tx>;
		qcom,iommu-group = <&ipa_eth_group1>;
		dma-coherent;
		iommus = <&apps_smmu 0x41 0x0>,
			 <&apps_smmu 0x42 0x0>,
			 <&apps_smmu 0x43 0x0>,
			 <&apps_smmu 0x44 0x0>,
			 <&apps_smmu 0x45 0x0>,
			 <&apps_smmu 0x46 0x0>,
			 <&apps_smmu 0x49 0x0>,
			 <&apps_smmu 0x4A 0x0>,
			 <&apps_smmu 0x4B 0x0>,
			 <&apps_smmu 0x4C 0x0>,
			 <&apps_smmu 0x4D 0x0>,
			 <&apps_smmu 0x4E 0x0>;

		reg = <0x23040000 0x14000>,
			<0x230BF000 0x1000>,
			<0x23054000 0x5100>,
			<0x00FFA000 0xE10>;
		reg-names = "stmmaceth", "rgmii","xpcs","serdes";
		clocks =<&gcc GCC_EEE_EMAC0_CLK>,
			<&gcc GCC_EMAC0_AXI_CLK>,
			<&gcc GCC_EMAC0_CC_SGMIIPHY_RX_CLK>,
			<&gcc GCC_EMAC0_CC_SGMIIPHY_TX_CLK>,
			<&gcc GCC_EMAC0_PHY_AUX_CLK>,
			<&gcc GCC_EMAC0_PTP_CLK>,
			<&gcc GCC_EMAC0_RGMII_CLK>,
			<&gcc GCC_EMAC0_RPCS_RX_CLK>,
			<&gcc GCC_EMAC0_RPCS_TX_CLK>,
			<&gcc GCC_EMAC0_SLV_AHB_CLK>,
			<&gcc GCC_EMAC0_XGXS_RX_CLK>,
			<&gcc GCC_EMAC0_XGXS_TX_CLK>,
			<&gcc GCC_EMAC0_CC_SGMIIPHY_RX_CLK_SRC>,
			<&gcc GCC_EMAC0_CC_SGMIIPHY_TX_CLK_SRC>,
			<&gcc GCC_EMAC0_SGMIIPHY_MAC_RCLK_SRC>,
			<&gcc GCC_EMAC0_SGMIIPHY_MAC_TCLK_SRC>,
			<&emac0_sgmiiphy_rclk>,
			<&emac0_sgmiiphy_tclk>,
			<&emac0_sgmiiphy_mac_rclk>,
			<&emac0_sgmiiphy_mac_tclk>,
			<&gcc GCC_EMAC_0_CLKREF_EN>;
		clock-names = "eee", "stmmaceth", "sgmii_rx",
		"sgmii_tx", "phyaux", "ptp_ref", "rgmii",
		"pcs_rx", "pcs_tx", "pclk", "xgxs_rx",
		"xgxs_tx", "sgmii_rclk_src", "sgmii_tclk_src",
		"sgmii_mac_rclk_src", "sgmii_mac_tclk_src", "sgmii_rclk",
		"sgmii_tclk", "sgmii_mac_rclk", "sgmii_mac_tclk","sgmi_ref";

		snps,ptp-ref-clk-rate = <230400000>;
		snps,ptp-req-clk-rate = <125000000>;

		interrupts-extended = <&intc GIC_SPI 360 IRQ_TYPE_LEVEL_HIGH>,
		<&tlmm 97 IRQ_TYPE_EDGE_FALLING>, <&intc GIC_SPI 417 IRQ_TYPE_LEVEL_HIGH>;
		interrupt-names = "macirq", "phy-intr", "pcs_intr";

		vreg_a_sgmii_1p2-supply = <&L1B>;
		vreg_a_sgmii_0p9-supply = <&L4B>;
		gdsc_emac-supply = <&gcc_emac0_gdsc>;
		pinctrl-names = "default","init";

		pinctrl-0 = <&emac0_mdc_active
			     &emac0_mdio_active
			     &emac0_pin_phy_intr_active
			     &emac0_phy_reset_state_active>;
		pinctrl-1 = <&emac0_mdc_inactive
			     &emac0_mdio_inactive
			     &emac0_pin_phy_intr_inactive
			     &emac0_phy_reset_state_inactive>;

		snps,reset-gpio = <&tlmm 96 1>;
		snps,crc_strip;

		interconnect-names = "axi_icc_path", "apb_icc_path";
		interconnects = <&system_noc MASTER_EMAC_0 &mc_virt SLAVE_EBI1>,
				<&gem_noc MASTER_APPSS_PROC &system_noc SLAVE_ETH0_CFG>;

		snps,tso;
		snps,pbl = <32>;
		tx-fifo-depth = <49152>;
		rx-fifo-depth = <20480>;
		snps,reset-active-low;
		snps,axi-config = <&stmmac_axi_setup>;

	};

	qcom,chd {
		compatible = "qcom,core-hang-detect";
		label = "core";
		qcom,threshold-arr = <0x17800058 0x17810058 0x17820058 0x17830058>;
		qcom,config-arr = <0x17800060 0x17810060 0x17820060 0x17830060>;
	};

	modem_pas: remoteproc-mss@04080000 {
		compatible = "qcom,sdxpinn-modem-pas";
		reg = <0x4080000 0x10000>;

		clocks = <&rpmhcc RPMH_CXO_CLK>;
		clock-names = "xo";

		cx-supply = <&VDD_CX_LEVEL>;
		cx-uV-uA = <RPMH_REGULATOR_LEVEL_TURBO 100000>;
		mx-supply = <&VDD_MODEM_LEVEL>;
		mx-uV-uA = <RPMH_REGULATOR_LEVEL_NOM_L1 100000>;
		reg-names = "cx", "mx";

		qcom,signal-aop;
		qcom,qmp = <&aoss_qmp>;
		memory-region = <&mpssadsp_mem &q6_mpss_dtb_mem &system_cma>;
		extended-memory-regions = <&mpss_dsmharq_mem>, <&mpss_dsmharq2_mem>, <&qlink_logging>;

		/* Inputs from mss */
		interrupts-extended = <&intc GIC_SPI 250 IRQ_TYPE_EDGE_RISING>,
					<&modem_smp2p_in 0 0>,
					<&modem_smp2p_in 2 0>,
					<&modem_smp2p_in 1 0>,
					<&modem_smp2p_in 3 0>,
					<&modem_smp2p_in 7 0>;

		interrupt-names = "wdog",
					"fatal",
					"handover",
					"ready",
					"stop-ack",
					"shutdown-ack";

		/* Outputs to mss */
		qcom,smem-states = <&modem_smp2p_out 0>;
		qcom,smem-state-names = "stop";

		glink_edge: glink-edge {
			qcom,remote-pid = <1>;
			transport = "smem";
			mboxes = <&ipcc_mproc IPCC_CLIENT_MPSS 3>;
			mbox-names = "mpss_smem";
			interrupt-parent = <&ipcc_mproc>;
			interrupts = <IPCC_CLIENT_MPSS 3 IRQ_TYPE_EDGE_RISING>;

			label = "modem";
			qcom,glink-label = "mpss";

			qcom,modem_qrtr {
				qcom,glink-channels = "IPCRTR";
				qcom,net-id = <6>;
				qcom,low-latency;
				qcom,intents = <0x4400 1
						0x800  5
						0x2000 3
						0x4400 1>;
			};

			qcom,modem_ds {
				qcom,glink-channels = "DS";
				qcom,intents = <0x4000 0x2>;
			};
		};
	};

	pmic_glink: qcom,pmic_glink {
		compatible = "qcom,pmic-glink";
		qcom,pmic-glink-channel = "PMIC_RTR_ADSP_APPS";
		qcom,subsys-name = "mpss";
		status = "disabled";

		ucsi: qcom,ucsi {
			compatible = "qcom,ucsi-glink";
		};

		qcom,battery_charger {
			compatible = "qcom,battery-charger";
			qcom,wireless-charging-not-supported;
			qcom,thermal-mitigation-step = <500000>;
		};
	};

	pmic_glink_log: qcom,pmic_glink_log {
		compatible = "qcom,pmic-glink";
		qcom,pmic-glink-channel = "PMIC_LOGS_ADSP_APPS";
		status = "disabled";

		qcom,battery_debug {
			compatible = "qcom,battery-debug";
		};

		qcom,charger_ulog_glink {
			compatible = "qcom,charger-ulog-glink";
		};

		pmic_glink_debug: qcom,pmic_glink_debug {
			compatible = "qcom,pmic-glink-debug";
			#address-cells = <1>;
			#size-cells = <0>;
			depends-on-supply = <&spmi_bus>;

			spmi@0 {
				reg = <0>;
				#address-cells = <2>;
				#size-cells = <0>;

				qcom,pm7550ba-debug@7 {
					compatible = "qcom,spmi-pmic";
					reg = <0x7 SPMI_USID>;
					qcom,can-sleep;
				};
			};
		};
	};

	kryo_erp {
		compatible = "arm,arm64-kryo-cpu-erp";
		interrupts = <GIC_PPI 0 IRQ_TYPE_LEVEL_HIGH>,
			<GIC_SPI 35 IRQ_TYPE_LEVEL_HIGH>;
		interrupt-names = "l1-l2-faultirq",
			"l3-scu-faultirq";
	};

	wdog: qcom,wdt@17410000 {
		compatible ="qcom,msm-watchdog";
		reg = <0x17410000 0x1000>;
		reg-names = "wdt-base";
		interrupts = <GIC_SPI 0 IRQ_TYPE_LEVEL_HIGH>,
			<GIC_SPI 1 IRQ_TYPE_LEVEL_HIGH>;
		status = "disabled";
	};

	qcom,msm-rtb {
		compatible = "qcom,msm-rtb";
		qcom,rtb-size = <0x100000>;
	};

	spmi_bus: qcom,spmi@c42d000 {
		compatible = "qcom,spmi-pmic-arb";
		reg = <0xc42d000 0x4000>,
		      <0xc400000 0x2800>,
		      <0xc500000 0x200000>,
		      <0xc440000 0x3c000>,
		      <0xc4c0000 0x10000>;
		reg-names = "cnfg", "core", "chnls", "obsrvr", "intr";
		interrupts-extended = <&pdc 1 IRQ_TYPE_LEVEL_HIGH>;
		interrupt-names = "periph_irq";
		interrupt-controller;
		#interrupt-cells = <4>;
		#address-cells = <2>;
		#size-cells = <0>;
		cell-index = <0>;
		qcom,channel = <0>;
		qcom,ee = <0>;
		qcom,bus-id = <0>;
	};

	spmi_debug_bus: qcom,spmi-debug@24b14000 {
		compatible = "qcom,spmi-pmic-arb-debug";
		reg = <0x24b14000 0x60>, <0x221c8784 0x4>;
		reg-names = "core", "fuse";
		clocks = <&aoss_qmp>;
		clock-names = "core_clk";
		qcom,fuse-enable-bit = <18>;
		#address-cells = <2>;
		#size-cells = <0>;
		depends-on-supply = <&spmi_bus>;

		qcom,pmk8550-debug@0 {
			compatible = "qcom,spmi-pmic";
			reg = <0x0 SPMI_USID>;
			#address-cells = <2>;
			#size-cells = <0>;
			qcom,can-sleep;
		};

		qcom,pmx75-debug@1 {
			compatible = "qcom,spmi-pmic";
			reg = <0x1 SPMI_USID>;
			#address-cells = <2>;
			#size-cells = <0>;
			qcom,can-sleep;
		};

		qcom,pm7550ba-debug@7 {
			compatible = "qcom,spmi-pmic";
			reg = <0x7 SPMI_USID>;
			#address-cells = <2>;
			#size-cells = <0>;
			qcom,can-sleep;
		};
	};

	qcom,rmtfs_sharedmem@0 {
		compatible = "qcom,sharedmem-uio";
		reg = <0x0 0x400000>;
		reg-names = "rmtfs";
		qcom,client-id = <0x00000001>;
	};

	thermal_zones: thermal-zones {
	};

	pcie_ep: qcom,pcie@0x48000000 {
		compatible = "qcom,pcie-ep";
		reg = <0x48003800 0x1000>,
			<0x48000000 0xf20>,
			<0x48000f20 0xa8>,
			<0x48001000 0x2000>,
			<0x01bf0000 0x4000>,
			<0x01bf7000 0x2000>,
			<0x01bf4000 0x1000>,
			<0x01fcb000 0x1000>,
			<0x0c2fa000 0x4>;
		reg-names = "msi", "dm_core", "elbi", "iatu",
			    "parf", "phy", "mmio", "tcsr_pcie_perst_en",
			    "aoss_cc_reset";

		#address-cells = <0>;
		interrupt-parent = <&pcie_ep>;
		interrupts = <0>;
		#interrupt-cells = <1>;
		interrupt-map-mask = <0xffffffff>;
		interrupt-map = <0 &intc GIC_SPI 140 IRQ_TYPE_LEVEL_HIGH>;
		interrupt-names = "int_global";

		pinctrl-names = "default";
		pinctrl-0 = <&pcie_ep_clkreq_default
			     &pcie_ep_perst_default
			     &pcie_ep_wake_default>;
		clkreq-gpio = <&tlmm 43 GPIO_ACTIVE_HIGH>;
		perst-gpio = <&tlmm 44 GPIO_ACTIVE_HIGH>;
		wake-gpio = <&tlmm 42 GPIO_ACTIVE_HIGH>;

		gdsc-vdd-supply = <&gcc_pcie_gdsc>;
		gdsc-phy-vdd-supply = <&gcc_pcie_phy_gdsc>;
		vreg-1p2-supply = <&L1B>;
		vreg-0p9-supply = <&L4B>;
		vreg-mx-supply = <&VDD_MXA_LEVEL>;
		qcom,vreg-1p2-voltage-level = <1200000 1200000 30000>;
		qcom,vreg-0p9-voltage-level = <912000 880000 177000>;
		qcom,vreg-mx-voltage-level = <RPMH_REGULATOR_LEVEL_MAX
					      RPMH_REGULATOR_LEVEL_NOM
					      0>;

		clocks = <&gcc GCC_PCIE_PIPE_CLK>,
			<&gcc GCC_PCIE_CFG_AHB_CLK>,
			<&gcc GCC_PCIE_MSTR_AXI_CLK>,
			<&gcc GCC_PCIE_SLV_AXI_CLK>,
			<&gcc GCC_PCIE_AUX_CLK>,
			<&gcc GCC_PCIE_0_CLKREF_EN>,
			<&gcc GCC_PCIE_SLEEP_CLK>,
			<&gcc GCC_PCIE_SLV_Q2A_AXI_CLK>,
			<&gcc GCC_PCIE_PIPE_CLK_SRC>,
			<&pcie_pipe_clk>,
			<&rpmhcc RPMH_CXO_CLK>;

		clock-names = "pcie_pipe_clk", "pcie_cfg_ahb_clk",
				"pcie_mstr_axi_clk", "pcie_slv_axi_clk",
				"pcie_aux_clk", "pcie_ldo",
				"pcie_sleep_clk",
				"pcie_slv_q2a_axi_clk",
				"pcie_pipe_clk_mux",
				"pcie_pipe_clk_ext_src",
				"pcie_0_ref_clk_src";

		resets = <&gcc GCC_PCIE_BCR>,
			<&gcc GCC_PCIE_PHY_BCR>;

		reset-names = "pcie_core_reset",
			"pcie_phy_reset";

		interconnect-names = "icc_path";
		interconnects = <&pcie_anoc MASTER_PCIE_0 &mc_virt SLAVE_EBI1>;

		qcom,pcie-vendor-id = /bits/ 16 <0x17cb>;
		qcom,pcie-device-id = /bits/ 16 <0x0309>;
		qcom,pcie-link-speed = <4>;
		qcom,pcie-phy-ver = <8>;
		qcom,pcie-active-config;
		qcom,pcie-aggregated-irq;
		qcom,pcie-mhi-a7-irq;
		qcom,pcie-cesta-clkreq-offset = <0x30a8>;
		qcom,phy-status-reg2 = <0x1214>;
		qcom,mhi-soc-reset-offset = <0xb001b8>;
		qcom,tcsr-reset-separation-offset = <0x3f8>;
		qcom,tcsr-hot-reset-offset = <0x3e8>;
		qcom,pcie-disconnect-req-reg-b = <6>;
		qcom,aoss-rst-clr;
		qcom,aux-clk = <0x13>;
		qcom,phy-init = <0x1240 0x01 0x0
				0x0030 0x18 0x0
				0x0034 0x03 0x0
				0x0078 0x01 0x0
				0x007c 0x00 0x0
				0x0080 0x51 0x0
				0x00ac 0x34 0x0
				0x0208 0x0c 0x0
				0x020c 0x0a 0x0
				0x0218 0x04 0x0
				0x0220 0x16 0x0
				0x0234 0x00 0x0
				0x029c 0x80 0x0
				0x02a0 0x7c 0x0
				0x02b4 0x05 0x0
				0x02d4 0x10 0x0
				0x02e8 0x0a 0x0
				0x030c 0x11 0x0
				0x0320 0x0b 0x0
				0x0348 0x1c 0x0
				0x0388 0x20 0x0
				0x0394 0x30 0x0
				0x03dc 0x09 0x0
				0x03f4 0xd4 0x0
				0x03f8 0x73 0x0
				0x03fc 0x18 0x0
				0x0400 0x9a 0x0
				0x0404 0x36 0x0
				0x0408 0xb6 0x0
				0x040c 0xee 0x0
				0x0410 0xcb 0x0
				0x0414 0xcb 0x0
				0x0418 0xe0 0x0
				0x041c 0xdf 0x0
				0x0420 0x78 0x0
				0x0424 0x76 0x0
				0x0428 0xff 0x0
				0x02e0 0x00 0x0
				0x0830 0x18 0x0
				0x0834 0x03 0x0
				0x0878 0x01 0x0
				0x087c 0x00 0x0
				0x0880 0x51 0x0
				0x08ac 0x34 0x0
				0x0a08 0x0c 0x0
				0x0a0c 0x0a 0x0
				0x0a18 0x04 0x0
				0x0a20 0x16 0x0
				0x0a34 0x00 0x0
				0x0a9c 0x80 0x0
				0x0aa0 0x7c 0x0
				0x0ab4 0x05 0x0
				0x0ad4 0x10 0x0
				0x0ae8 0x0a 0x0
				0x0b0c 0x11 0x0
				0x0b20 0x0b 0x0
				0x0b48 0x1c 0x0
				0x0b88 0x20 0x0
				0x0b94 0x30 0x0
				0x0bdc 0x09 0x0
				0x0bf4 0xd4 0x0
				0x0bf8 0x73 0x0
				0x0bfc 0x18 0x0
				0x0c00 0x9a 0x0
				0x0c04 0x36 0x0
				0x0c08 0xb6 0x0
				0x0c0c 0xee 0x0
				0x0c10 0xcb 0x0
				0x0c14 0xcb 0x0
				0x0c18 0xe0 0x0
				0x0c1c 0xdf 0x0
				0x0c20 0x78 0x0
				0x0c24 0x76 0x0
				0x0c28 0xff 0x0
				0x0ae0 0x00 0x0
				0x0ea0 0x01 0x0
				0x0eb4 0x00 0x0
				0x0ec4 0x02 0x0
				0x0ec8 0x0d 0x0
				0x0ed4 0xd4 0x0
				0x0ed8 0x12 0x0
				0x0edc 0xdb 0x0
				0x0ee0 0x9a 0x0
				0x0ee4 0x35 0x0
				0x0ee8 0xb6 0x0
				0x0eec 0x64 0x0
				0x0ef0 0x1f 0x0
				0x0ef4 0x1f 0x0
				0x0ef8 0x1f 0x0
				0x0efc 0x1f 0x0
				0x0f00 0x1f 0x0
				0x0f04 0x1f 0x0
				0x0f0c 0x1f 0x0
				0x0f14 0x1f 0x0
				0x0f1c 0x1f 0x0
				0x0f28 0x5b 0x0
				0x1010 0x28 0x0
				0x1014 0x17 0x0
				0x1018 0x03 0x0
				0x101c 0x04 0x0
				0x1020 0xff 0x0
				0x1024 0x09 0x0
				0x1028 0x28 0x0
				0x103c 0x12 0x0
				0x1040 0xfb 0x0
				0x1044 0x00 0x0
				0x1070 0x34 0x0
				0x1074 0x11 0x0
				0x1078 0x01 0x0
				0x107c 0x0a 0x0
				0x1080 0xff 0x0
				0x1084 0x04 0x0
				0x1088 0x19 0x0
				0x109c 0x00 0x0
				0x10a0 0xfb 0x0
				0x10a4 0x00 0x0
				0x10bc 0x06 0x0
				0x10d8 0x40 0x0
				0x10dc 0x14 0x0
				0x10e4 0x07 0x0
				0x10f4 0x1f 0x0
				0x1110 0x00 0x0
				0x1120 0x46 0x0
				0x1124 0x04 0x0
				0x1140 0x14 0x0
				0x1170 0xa0 0x0
				0x1174 0x06 0x0
				0x1184 0x88 0x0
				0x1188 0x14 0x0
				0x1198 0x0f 0x0
				0x1378 0x2e 0x0
				0x1390 0xcc 0x0
				0x13f8 0x00 0x0
				0x13fc 0x22 0x0
				0x129c 0x83 0x0
				0x12a0 0x09 0x0
				0x12a4 0xa2 0x0
				0x1450 0x02 0x0
				0x1478 0x10 0x0
				0x14a0 0x16 0x0
				0x14f0 0x27 0x0
				0x14f4 0x27 0x0
				0x1508 0x02 0x0
				0x155c 0x2e 0x0
				0x157c 0x03 0x0
				0x1584 0x28 0x0
				0x13dc 0x04 0x0
				0x13e0 0x02 0x0
				0x1418 0xc0 0x0
				0x158c 0x0f 0x0
				0x15ac 0xf2 0x0
				0x15c0 0xf2 0x0
				0x1370 0x17 0x0
				0x1a38 0x00 0x0
				0x1e38 0x00 0x0
				0x1e24 0x00 0x0
				0x1e28 0x00 0x0
				0x1200 0x00 0x0
				0x1244 0x03 0x0>;

		status = "disabled";
	};

	mhi_device: mhi_dev@1bf4000 {
		compatible = "qcom,msm-mhi-dev";
		reg = <0x1bf4000 0x1000>;
		reg-names = "mhi_mmio_base";
		qcom,mhi-ep-msi = <0>;
		qcom,mhi-version = <0x1000000>;
		qcom,use-mhi-dma-software-channel;
		interrupts = <GIC_SPI 145 IRQ_TYPE_LEVEL_HIGH>;
		interrupt-names = "mhi-device-inta";
		qcom,mhi-ifc-id = <0x030917cb>;
		qcom,mhi-interrupt;
		qcom,no-m0-timeout;
		qcom,mhi-has-smmu;
		iommus = <&apps_smmu 0x800 0x0>;
		qcom,iommu-dma = "bypass";

		status = "disabled";
	};

	mhi_net_device: qcom,mhi_net_dev {
		compatible = "qcom,msm-mhi-dev-net";
		status = "disabled";
	};

	qcom,sps {
		compatible = "qcom,msm-sps-4k";
		qcom,pipe-attr-ee;
	};

	qcom_tzlog: tz-log@14680720 {
		compatible = "qcom,tz-log";
		reg = <0x14680720 0x3000>;
		qcom,hyplog-enabled;
		hyplog-address-offset = <0x410>;
		hyplog-size-offset = <0x414>;
	};

	qcom,secure-buffer {
		compatible = "qcom,secure-buffer";
	};

	qcom,mem-buf {
		compatible = "qcom,mem-buf";
		qcom,mem-buf-capabilities = "supplier";
		qcom,vmid = <3>;
	};

	qcom,mem-buf-msgq {
		compatible = "qcom,mem-buf-msgq";
	};

	llcc_device: cache-controller@19200000 {
		compatible = "qcom,sdxpinn-llcc", "qcom,llcc-v41";
		reg = <0x19200000 0x200000>;
		reg-names = "llcc_base";
		interrupts = <GIC_SPI 399 IRQ_TYPE_LEVEL_HIGH>;
		cap-based-alloc-and-pwr-collapse;
		memory-region = <&llcc_tcm_mem>;
	};

	clk_virt: interconnect@0 {
		compatible = "qcom,sdxpinn-clk_virt";
		#interconnect-cells = <1>;
		qcom,bcm-voter-names = "hlos";
		qcom,bcm-voters = <&apps_bcm_voter>;
		clocks = <&rpmhcc RPMH_QPIC_CLK>;
	};

	mc_virt: interconnect@1 {
		compatible = "qcom,sdxpinn-mc_virt";
		#interconnect-cells = <1>;
		qcom,bcm-voter-names = "hlos";
		qcom,bcm-voters = <&apps_bcm_voter>;
	};

	dc_noc: interconnect@190E0000 {
		compatible = "qcom,sdxpinn-dc_noc";
		reg = <0x190E0000 0x8200>;
		#interconnect-cells = <1>;
		qcom,bcm-voter-names = "hlos";
		qcom,bcm-voters = <&apps_bcm_voter>;
	};

	gem_noc: interconnect@19100000 {
		compatible = "qcom,sdxpinn-gem_noc";
		reg = <0x19100000 0x34080>;
		#interconnect-cells = <1>;
		qcom,bcm-voter-names = "hlos";
		qcom,bcm-voters = <&apps_bcm_voter>;
	};

	pcie_anoc: interconnect@16C0000 {
		compatible = "qcom,sdxpinn-pcie_anoc";
		reg = <0x16C0000 0x14200>;
		#interconnect-cells = <1>;
		qcom,bcm-voter-names = "hlos";
		qcom,bcm-voters = <&apps_bcm_voter>;
	};

	system_noc: interconnect@1640000 {
		compatible = "qcom,sdxpinn-system_noc";
		reg = <0x1640000 0x4B400>;
		#interconnect-cells = <1>;
		qcom,bcm-voter-names = "hlos";
		qcom,bcm-voters = <&apps_bcm_voter>;
		clocks = <&gcc GCC_SYS_NOC_MVMSS_CLK>;
	};

	qcom,msm_gsi {
		compatible = "qcom,msm_gsi";
	};

	qcom,rmnet-ipa {
		compatible = "qcom,rmnet-ipa3";
		qcom,rmnet-ipa-ssr;
		qcom,ipa-advertise-sg-support;
		qcom,ipa-napi-enable;
	};

	qcom,ipa_fws {
		compatible = "qcom,pil-tz-generic";
		qcom,pas-id = <0xf>;
		qcom,firmware-name = "ipa_fws";
		status = "disabled";
	};

	ipa_eth_group1: ipa_eth_group1 {
		qcom,iommu-dma-addr-pool = <0x80000000 0x07E00000>;
		qcom,iommu-dma = "fastmap";
	};

	ipa_eth_group2: ipa_eth_group2 {
		qcom,iommu-dma-addr-pool = <0x87f10000 0x07f00000>;
		qcom,iommu-dma = "fastmap";
	};

	ipa_hw: qcom,ipa@03e00000 {
		compatible = "qcom,ipa";
		mboxes = <&qmp_aop 0>;
		reg =
			<0x3e00000 0xb0000>,
			<0x3e00000 0x100000>;
		reg-names = "ipa-base", "gsi-base";
		qcom,ipa-cfg-offset = <0x0114000>;
		interrupts =
			<0 314 IRQ_TYPE_LEVEL_HIGH>,
			<0 308 IRQ_TYPE_LEVEL_HIGH>;
		interrupt-names = "ipa-irq", "gsi-irq";
		qcom,ipa-hw-ver = <25>; /* IPA core version = IPAv6.0 */
		qcom,ipa-hw-mode = <0>; // IPA_HW_MODE_NORMAL
		qcom,platform-type = <0>; /* MDM platform */
		qcom,ee = <0>;
		qcom,entire-ipa-block-size = <0x200000>;
		qcom,use-ipa-tethering-bridge;
		qcom,use-tput-estmation-pipe;
		qcom,mhi-event-ring-id-limits = <9 15>; // need to find the values for Pinnacles
		qcom,modem-cfg-emb-pipe-flt;
		qcom,use-xbl-boot;
		qcom,arm-smmu;
		qcom,smmu-fast-map;
		qcom,use-64-bit-dma-mask;
		qcom,ipa-wdi3-over-gsi;
		qcom,ipa-wdi3-holb-2g = <15>;
		qcom,ipa-wdi3-holb-5g = <31>;
		qcom,ipa-endp-delay-wa-v2;
		qcom,tx-wrapper-cache-max-size = <400>;
		qcom,ipa-gpi-event-rp-ddr;
		qcom,ulso-supported;
		qcom,ulso-ip-id-min-linux-val = <0>;
		qcom,ulso-ip-id-max-linux-val = <0xffff>;
		qcom,ulso-ip-id-min-windows-val = <0>;
		qcom,ulso-ip-id-max-windows-val = <0x7fff>;
		qcom,register-collection-on-crash;
		qcom,testbus-collection-on-crash;
		qcom,non-tn-collection-on-crash;
		qcom,wan-use-skb-page;
		clock-names = "core_clk";
		clocks = <&rpmhcc RPMH_IPA_CLK>;
		qcom,interconnect,num-cases = <5>;
		qcom,interconnect,num-paths = <3>;
		qcom,max_num_smmu_cb = <7>;
		qcom,filter-start-id = <768>;
		qcom,ipa-iemac;
		qcom,lan-rx-napi;
		qcom,tx-napi;
		qcom,tx-poll;
		qcom,lan-coal-enable;

		/* Boot Config Information */
		nvmem-cells = <&boot_config>;
		nvmem-cell-names = "boot_conf";
		qcom,fast-boot-mask = <0x1e>;
		qcom,host-bypass-mask = <0x40>;
		qcom,fast-boot-values = <0x5 0x7>;

		interconnects = <&system_noc MASTER_IPA &gem_noc SLAVE_LLCC>,
		<&mc_virt MASTER_LLCC &mc_virt SLAVE_EBI1>,
		<&gem_noc MASTER_APPSS_PROC &system_noc SLAVE_IPA_CFG>;

		interconnect-names = "ipa_to_llcc", "llcc_to_ebi1", "appss_to_ipa";
		/* No vote */
		qcom,no-vote =
		<0 0 0 0 0 0>;

		/* SVS2 */
		qcom,svs2 =
		<18000 0 600000 1900000 0 76800>;

		/* SVS */
		qcom,svs =
		<400000 0 1200000 2800000 0 150000>;

		/* NOMINAL */
		qcom,nominal =
		<670000 0 2400000 5500000 0 400000>;

		/* TURBO */
		qcom,turbo =
		<1380000 0 3600000 5500000 0 400000>;

		qcom,bus-vector-names = "MIN", "SVS2", "SVS", "NOMINAL",
		"TURBO";
		qcom,throughput-threshold = <2000 2500 10000>;
		qcom,scaling-exceptions = "wdi", "1400", "4800", "10000";

		ipa_smmu_ap: ipa_smmu_ap {
			compatible = "qcom,ipa-smmu-ap-cb";
			iommus = <&apps_smmu 0x420 0x0>;
			qcom,iommu-dma-addr-pool = <0x20000000 0x20000000>;
			qcom,additional-mapping =
				/* modem tables in IMEM */
				<0x14688000 0x14688000 0x2000>;
			qcom,iommu-geometry = <0x0 0xA0000000>;
			qcom,iommu-dma = "fastmap";
			dma-coherent;
			qcom,ipa-q6-smem-size = <45056>;
		};

		ipa_wlan_group: ipa_wlan_group {
			qcom,iommu-dma = "atomic";
			dma-coherent;
		};

		ipa_smmu_wlan: ipa_smmu_wlan {
			compatible = "qcom,ipa-smmu-wlan-cb";
			iommus = <&apps_smmu 0x421 0x0>;
			qcom,shared-cb;
			qcom,iommu-group = <&ipa_wlan_group>;
			dma-coherent;
		};

		ipa_smmu_uc: ipa_smmu_uc {
			compatible = "qcom,ipa-smmu-uc-cb";
			iommus = <&apps_smmu 0x422 0x0>;
			qcom,iommu-dma-addr-pool = <0x20000000 0x20000000>;
			qcom,iommu-dma = "atomic";
			dma-coherent;
		};

		ipa_smmu_wlan1: ipa_smmu_wlan1 {
			compatible = "qcom,ipa-smmu-wlan1-cb";
			iommus = <&apps_smmu 0x423 0x0>;
			qcom,shared-cb;
			qcom,iommu-group = <&ipa_wlan_group>;
			dma-coherent;
		};

		ipa_smmu_wlan2: ipa_smmu_wlan2 {
			compatible = "qcom,ipa-smmu-wlan2-cb";
			iommus = <&apps_smmu 0x424 0x0>;
			qcom,shared-cb;
			qcom,iommu-group = <&ipa_wlan_group>;
			dma-coherent;
		};

		ipa_smmu_eth: ipa_smmu_eth {
			compatible = "qcom,ipa-smmu-eth-cb";
			iommus = <&apps_smmu 0x425 0x0>;
			qcom,shared-cb;
			qcom,iommu-group = <&ipa_eth_group1>;
			dma-coherent;
		};

		ipa_smmu_eth1: ipa_smmu_eth1 {
			compatible = "qcom,ipa-smmu-eth1-cb";
			iommus = <&apps_smmu 0x426 0x0>;
			qcom,shared-cb;
			qcom,iommu-group = <&ipa_eth_group2>;
			dma-coherent;
		};

		/* smp2p information */

		qcom,smp2p_map_ipa_1_out {
			compatible = "qcom,smp2p-map-ipa-1-out";
			qcom,smem-states = <&smp2p_ipa_1_out 0>;
			qcom,smem-state-names = "ipa-smp2p-out";
		};

		qcom,smp2p_map_ipa_1_in {
			compatible = "qcom,smp2p-map-ipa-1-in";
			interrupts-extended = <&smp2p_ipa_1_in 0 0>;
			interrupt-names = "ipa-smp2p-in";
		};

	};
};

&firmware {
	qcom_scm {
		compatible = "qcom,scm";
		qcom,dload-mode = <&tcsr 0x13000>;
	};

	qtee_shmbridge {
		compatible = "qcom,tee-shared-memory-bridge";
	};

	qcom_smcinvoke {
		compatible = "qcom,smcinvoke";
	};
};

#include "ipcc-test-sdxpinn.dtsi"
#include "sdxpinn-regulators.dtsi"
#include "sdxpinn-coresight.dtsi"
#include "sdxpinn-debug.dtsi"
#include "sdxpinn-pinctrl.dtsi"
#include "sdxpinn-pcie.dtsi"
#include "sdxpinn-usb.dtsi"
#include "sdxpinn-qupv3.dtsi"
#include "msm-arm-smmu-sdxpinn.dtsi"
#include "sdxpinn-dma-heaps.dtsi"
#include "sdxpinn-thermal.dtsi"

&qupv3_se1_2uart {
	status = "ok";
};
